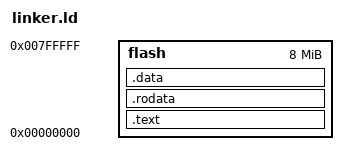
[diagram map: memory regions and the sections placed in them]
OUTPUT_FORMAT("elf32-lm32")
ENTRY(_start)

__DYNAMIC = 0;

MEMORY {
	flash : ORIGIN = 0x00000000, LENGTH = 0x800000   /* 8M */
}

SECTIONS
{
	.text :
	{
		_ftext = .;
		*(.text .stub .text.* .gnu.linkonce.t.*)
		_etext = .;
	} > flash

	.rodata :
	{
		. = ALIGN(4);
		_frodata = .;
		*(.rodata .rodata.* .gnu.linkonce.r.*)
		*(.rodata1)
		_erodata = .;
	} > flash

	.data :
	{
		. = ALIGN(4);
		_fdata = .;
		*(.data .data.* .gnu.linkonce.d.*)
		*(.data1)
		_gp = ALIGN(16);
		*(.sdata .sdata.* .gnu.linkonce.s.*)
		_edata = .;
	} > flash
}
